AUTOSAR XML (schema 4-2-2)
package /Components
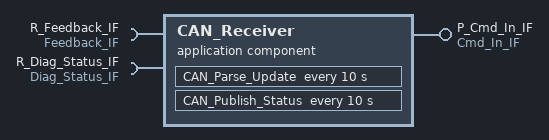
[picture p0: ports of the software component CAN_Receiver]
  application sw component type CAN_Receiver
    provide port P_Cmd_In_IF: provided-interface=Cmd_In_IF
    require port R_Feedback_IF: required-interface=Feedback_IF
    require port R_Diag_Status_IF: required-interface=Diag_Status_IF
    behavior CAN_Receiver_IB
      init event CAN_Receiver_Init: start-on-event=CAN_Publish_Status
      timing event CAN_Receiver_Cycle_Parse: start-on-event=CAN_Parse_Update, period=10
      timing event CAN_Receiver_Cycle_Publish: start-on-event=CAN_Publish_Status, period=10
      runnable CAN_Parse_Update: minimum-start-interval=10
        data-send-points:
          4 x access:
            VA_TX_m1_speed_cmd: accessed-variable=P_Cmd_In_IF.m1_speed_cmd
            VA_TX_m1_pos_cmd: accessed-variable=P_Cmd_In_IF.m1_pos_cmd
            VA_TX_m2_speed_cmd: accessed-variable=P_Cmd_In_IF.m2_speed_cmd
            VA_TX_m2_pos_cmd: accessed-variable=P_Cmd_In_IF.m2_pos_cmd
      runnable CAN_Publish_Status: minimum-start-interval=10
        data-receive-point-by-arguments:
          6 x access:
            VA_RX_m1_speed_meas: accessed-variable=R_Feedback_IF.m1_speed_meas
            VA_RX_m1_pos_meas: accessed-variable=R_Feedback_IF.m1_pos_meas
            VA_RX_m2_speed_meas: accessed-variable=R_Feedback_IF.m2_speed_meas
            VA_RX_m2_pos_meas: accessed-variable=R_Feedback_IF.m2_pos_meas
            VA_RX_diag_status: accessed-variable=R_Diag_Status_IF.diag_status
            VA_RX_fault_code: accessed-variable=R_Diag_Status_IF.fault_code
